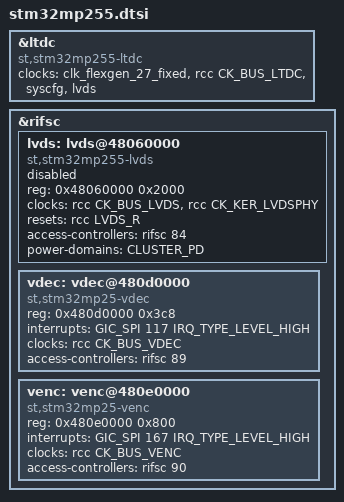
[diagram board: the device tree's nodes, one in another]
// SPDX-License-Identifier: (GPL-2.0-or-later OR BSD-3-Clause)
/*
 * Copyright (C) STMicroelectronics 2023 - All Rights Reserved
 * Author: Alexandre Torgue <alexandre.torgue@foss.st.com> for STMicroelectronics.
 */
#include "stm32mp253.dtsi"

&ltdc {
	compatible = "st,stm32mp255-ltdc";
	clocks = <&clk_flexgen_27_fixed>, <&rcc CK_BUS_LTDC>, <&syscfg>, <&lvds>;
	clock-names = "lcd", "bus", "ref", "lvds";
};

&rifsc {
	lvds: lvds@48060000 {
		compatible = "st,stm32mp255-lvds", "st,stm32mp25-lvds";
		reg = <0x48060000 0x2000>;
		#clock-cells = <0>;
		clocks = <&rcc CK_BUS_LVDS>, <&rcc CK_KER_LVDSPHY>;
		clock-names = "pclk", "ref";
		resets = <&rcc LVDS_R>;
		access-controllers = <&rifsc 84>;
		power-domains = <&CLUSTER_PD>;
		status = "disabled";
	};

	vdec: vdec@480d0000 {
		compatible = "st,stm32mp25-vdec";
		reg = <0x480d0000 0x3c8>;
		interrupts = <GIC_SPI 117 IRQ_TYPE_LEVEL_HIGH>;
		clocks = <&rcc CK_BUS_VDEC>;
		access-controllers = <&rifsc 89>;

	};

	venc: venc@480e0000 {
		compatible = "st,stm32mp25-venc";
		reg = <0x480e0000 0x800>;
		interrupts = <GIC_SPI 167 IRQ_TYPE_LEVEL_HIGH>;
		clocks = <&rcc CK_BUS_VENC>;
		access-controllers = <&rifsc 90>;
	};
};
